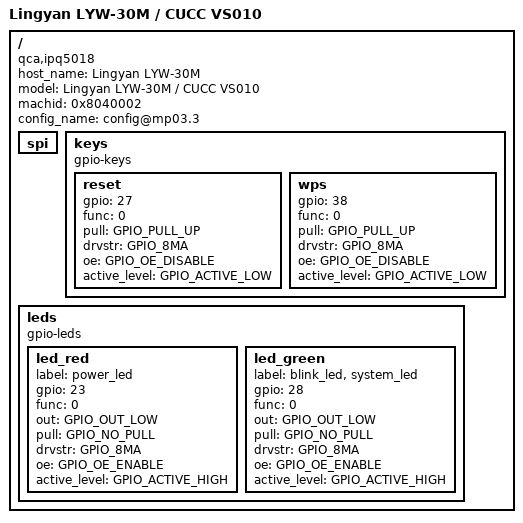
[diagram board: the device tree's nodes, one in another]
/*
 * Lingyan LYW-30M (CMCC) / CUCC VS010 / CUCC VS010 MAX, board AX3000_Q06.
 * One PCB sold under three carrier names; stock boot chain reports
 * IPQ5018 AP-MP03.3, board ID 0x8040002 (CDT), and boots FIT config@mp03.3.
 *
 * Buttons and LEDs match the stock kernel DTB (config@mp03.3):
 * WPS GPIO38, RESET GPIO27, LEDs GPIO23 (power) and GPIO28 (mesh).
 * Board description adapted from Jioyzen/uboot-qsdk12.5-build
 * (branch lyw-30m-recovery, ipq5018-lyw-30m-uboot.dts), GPL-2.0.
 *
 * Units flashed with the uBootKit CUCC VS010 flow carry a modified CDT
 * (MP02.1, 0x8040000); they need ipq5018_cucc_vs010 instead.
 *
 * SPDX-License-Identifier: GPL-2.0
 */
#include "ipq5018-mp03.3.dts"

/ {
	host_name = "Lingyan LYW-30M";
	model = "Lingyan LYW-30M / CUCC VS010";
	compatible = "qca,ipq5018", "qca,ipq5018-mp03.3";
	machid = <0x8040002>;
	config_name = "config@mp03.3";

	/* The OEM MP03.3 DTB configures only the two QUP SPI BAM pipes. */
	spi {
		/delete-property/ wr_pipe_1;
		/delete-property/ rd_pipe_1;
		/delete-property/ wr_pipe_2;
		/delete-property/ rd_pipe_2;
	};

	keys {
		compatible = "gpio-keys";

		reset {
			gpio = <27>;
			func = <0>;
			pull = <GPIO_PULL_UP>;
			drvstr = <GPIO_8MA>;
			oe = <GPIO_OE_DISABLE>;
			active_level = <GPIO_ACTIVE_LOW>;
		};

		wps {
			gpio = <38>;
			func = <0>;
			pull = <GPIO_PULL_UP>;
			drvstr = <GPIO_8MA>;
			oe = <GPIO_OE_DISABLE>;
			active_level = <GPIO_ACTIVE_LOW>;
		};
	};

	leds {
		compatible = "gpio-leds";

		led_red {
			label = "power_led";
			gpio = <23>;
			func = <0>;
			out = <GPIO_OUT_LOW>;
			pull = <GPIO_NO_PULL>;
			drvstr = <GPIO_8MA>;
			oe = <GPIO_OE_ENABLE>;
			active_level = <GPIO_ACTIVE_HIGH>;
		};

		led_green {
			label = "blink_led", "system_led";
			gpio = <28>;
			func = <0>;
			out = <GPIO_OUT_LOW>;
			pull = <GPIO_NO_PULL>;
			drvstr = <GPIO_8MA>;
			oe = <GPIO_OE_ENABLE>;
			active_level = <GPIO_ACTIVE_HIGH>;
		};
	};

};
